AUTOSAR XML (schema 4-0-3)
standard types defined: UInt32, UInt8
package /AUTOSAR_Platform/DataConstrs
  range DC_UInt8: raw 0..255
package /PATAC/MSM/ComponentTypes
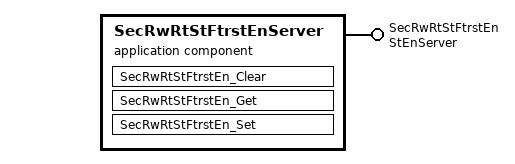
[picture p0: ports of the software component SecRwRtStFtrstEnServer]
  application sw component type SecRwRtStFtrstEnServer
    provide port SecRwRtStFtrstEn: provided-com-specs=[{operation=Clear, queue-length=1}, {operation=Get, queue-length=1}, {operation=Set, queue-length=1}], provided-interface=StEnServer
    behavior SecRwRtStFtrstEnServer_InternalBehavior
      operation invoked event OIT_SecRwRtStFtrstEn_Clear_SecRwRtStFtrstEn_Clear: start-on-event=SecRwRtStFtrstEn_Clear, operation=SecRwRtStFtrstEn.Clear
      operation invoked event OIT_SecRwRtStFtrstEn_Get_SecRwRtStFtrstEn_Get: start-on-event=SecRwRtStFtrstEn_Get, operation=SecRwRtStFtrstEn.Get
      operation invoked event OIT_SecRwRtStFtrstEn_Set_SecRwRtStFtrstEn_Set: start-on-event=SecRwRtStFtrstEn_Set, operation=SecRwRtStFtrstEn.Set
      runnable SecRwRtStFtrstEn_Clear
      runnable SecRwRtStFtrstEn_Get
      runnable SecRwRtStFtrstEn_Set
  swc implementation SecRwRtStFtrstEnServer_Implementation: behavior=SecRwRtStFtrstEnServer_InternalBehavior
    code-descriptors:
      code Default: artifact-descriptors=autosar-engineering-object={short-label=Default, category=SWSRC}
package /PATAC/MSM/ModeAdjust/PortInterface
  client server interface StEnServer
    operation Clear
      arg data: type=UInt8, direction=IN, server-argument-impl-policy=USE-ARGUMENT-TYPE
    operation Get
      arg data: type=UInt32, direction=OUT, server-argument-impl-policy=USE-ARGUMENT-TYPE
    operation Set
      arg data: type=UInt8, direction=IN, server-argument-impl-policy=USE-ARGUMENT-TYPE
